# MCXN947_cm33_core0 register map
Vendor: nxp.com; File version: 1.0
CPU: CM33 r2p0, little endian, MPU, FPU, VTOR, 3 interrupt priority bits
Registers are 32-bit, read-write, reset 0x0 unless marked. A register's access mark holds for its fields unless they carry their own. Offsets are from the block's base; [hi:lo] are bit positions.

## CACHE64_POLSEL0 — CACHE64_POLSEL
Base 0x4001B000; alternate view of CACHE64_CTRL0
0x14 REG0_TOP reset 0xAAAA800 — Region 0 Top Boundary
  [28:10] REG0_TOP — Upper Limit Of Region 0
0x18 REG1_TOP reset 0x15555400 — Region 1 Top Boundary
  [28:10] REG1_TOP — Upper Limit Of Region 1
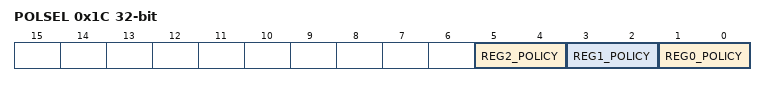
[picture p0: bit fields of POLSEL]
0x1C POLSEL — Policy Select
  [5:4] REG2_POLICY — Policy Select For Region 2
    0=REG2_00 (Noncacheable); 1=REG2_01 (Write-through); 2=REG2_10 (Write-back); 3=REG2_11 (Invalid)
  [3:2] REG1_POLICY — Policy Select For Region 1
    0=REG1_00 (Noncacheable); 1=REG1_01 (Write-through); 2=REG1_10 (Write-back); 3=REG1_11 (Invalid)
  [1:0] REG0_POLICY — Policy Select For Region 0
    0=REG0_00 (Noncacheable); 1=REG0_01 (Write-through); 2=REG0_10 (Write-back); 3=REG0_11 (Invalid)

## GDET0
Base 0x40024000
Same registers: GDET1 0x40025000
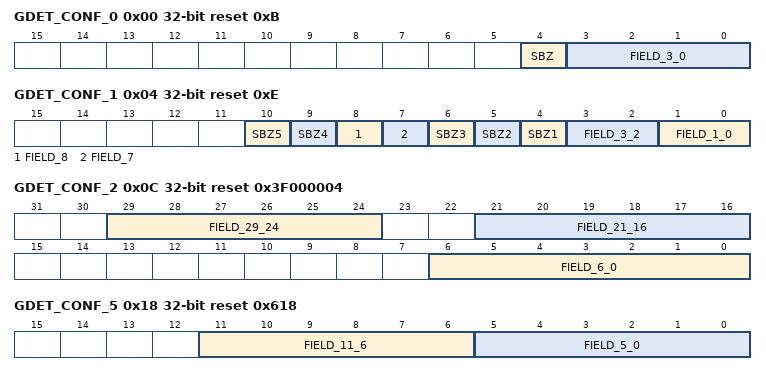
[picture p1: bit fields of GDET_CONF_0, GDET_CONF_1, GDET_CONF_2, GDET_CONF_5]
0x00 GDET_CONF_0 reset 0xB — GDET Configuration 0 Register
  [4] SBZ — Should Be Left to Zero
  [3:0] FIELD_3_0 — GDET Configuration 0 Field 3_0
0x04 GDET_CONF_1 reset 0xE — GDET Configuration 1 Register
  [10] SBZ5 — Should Be Left to Zero
  [9] SBZ4 — Should Be Left to Zero
  [8] FIELD_8 — GDET Configuration 1 Field 8
  [7] FIELD_7 — GDET Configuration 1 Field 7
  [6] SBZ3 — Should Be Left to Zero
  [5] SBZ2 — Should Be Left to Zero
  [4] SBZ1 — Should Be Left to Zero
  [3:2] FIELD_3_2 — GDET Configuration 1 Field 3_2
  [1:0] FIELD_1_0 — GDET Configuration 1 Field 1_0
0x08 GDET_ENABLE1 — GDET Enable Register
  [0] EN1 — If set, the detector will be clock gated
0x0C GDET_CONF_2 reset 0x3F000004 — GDET Configuration 2 Register
  [29:24] FIELD_29_24 — GDET Configuration 2 Field 29_24
  [21:16] FIELD_21_16 — GDET Configuration 2 Field 21_16
  [6:0] FIELD_6_0 — GDET Configuration 2 Field 6_0
0x10 GDET_CONF_3 reset 0x4 — GDET Configuration 3 Register
  [6:0] FIELD_6_0 — GDET Configuration 3 Field 6_0
0x14 GDET_CONF_4 reset 0x4 — GDET Configuration 4 Register
  [6:0] FIELD_6_0 — GDET Configuration 4 Field 6_0
0x18 GDET_CONF_5 reset 0x618 — GDET Configuration 5 Register
  [11:6] FIELD_11_6 — GDET Configuration 5 Field 11_6
  [5:0] FIELD_5_0 — GDET Configuration 5 Field 5_0
0xFC0 GDET_RESET
  [3] SFT_RST — Soft Reset for the Core Reset
0xFC4 GDET_TEST
  [0] SBZ — Should Be Left to Zero
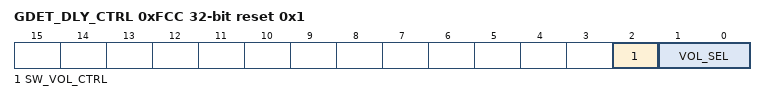
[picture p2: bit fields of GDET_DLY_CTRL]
0xFCC GDET_DLY_CTRL reset 0x1 — GDET Delay Control Register
  [2] SW_VOL_CTRL — Select the Control of the Trim Code to the Delay Line
  [1:0] VOL_SEL — GDET Delay Control of the Voltage Mode

## PUF_CTRL — PUF Key Context Management
Base 0x4002C000; alternate view of PUF
Same registers: PUF_CTRL_ALIAS1 0x4002D000 (alternate view of PUF_ALIAS1), PUF_CTRL_ALIAS2 0x4002E000 (alternate view of PUF_ALIAS2), PUF_CTRL_ALIAS3 0x4002F000 (alternate view of PUF_ALIAS3)
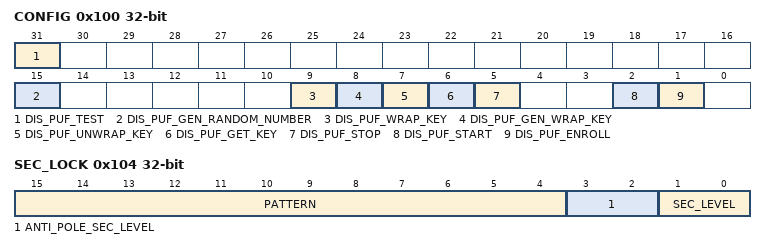
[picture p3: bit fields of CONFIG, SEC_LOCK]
0x100 CONFIG — PUF command blocking configuration
  [all] fields
    0=ENABLE (Command enabled); 1=DISABLE (Command disabled)
  [31] DIS_PUF_TEST — Disable PUF test command
  [15] DIS_PUF_GEN_RANDOM_NUMBER — Disable PUF generate and wrap key command
  [9] DIS_PUF_WRAP_KEY — Disable PUF wrap key command
  [8] DIS_PUF_GEN_WRAP_KEY — Disable PUF generate and wrap key command
  [7] DIS_PUF_UNWRAP_KEY — Disable PUF unwrap key command
  [6] DIS_PUF_GET_KEY — Disable PUF get key command
  [5] DIS_PUF_STOP — Disable PUF stop command
  [2] DIS_PUF_START — Disable PUF start command
  [1] DIS_PUF_ENROLL — Disable PUF enroll command
0x104 SEC_LOCK — Security level lock
  [15:4] PATTERN
  [3:2] ANTI_POLE_SEC_LEVEL — Anti-pole of security level
    0=NONSECURE_NONPRIV_MASTER (Secure and privileged Master); 1=NONSECURE_PRIV_MASTER (Secure and non-privileged Master); 2=SECURE_NONPRIV_MASTER (Non-secure and privileged Master); 3=SECURE_PRIV_MASTER (Non-secure and non-privileged Master)
  [1:0] SEC_LEVEL — Security Level
    0=NONSECURE_NONPRIV_MASTER (Non-secure and non-privileged Master); 1=NONSECURE_PRIV_MASTER (Non-secure and privileged Master); 2=SECURE_NONPRIV_MASTER (Secure and non-privileged Master); 3=SECURE_PRIV_MASTER (Secure and privileged Master)
0x108 APP_CTX_MASK — Application defined context mask
  [31:0] APP_CTX_MASK — Application defined context
